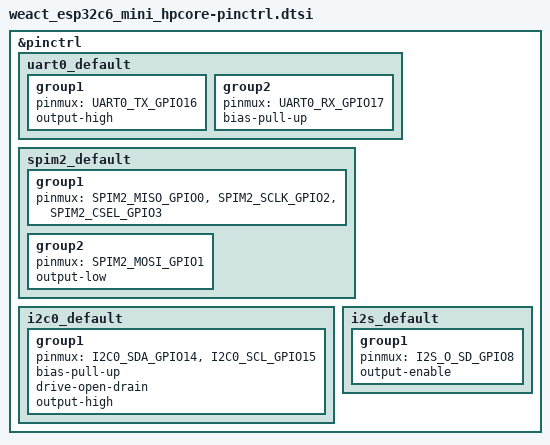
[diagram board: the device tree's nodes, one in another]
/*
 * Copyright (c) 2025 Siratul Islam
 *
 * SPDX-License-Identifier: Apache-2.0
 */

#include <zephyr/dt-bindings/pinctrl/esp-pinctrl-common.h>
#include <dt-bindings/pinctrl/esp32c6-pinctrl.h>
#include <zephyr/dt-bindings/pinctrl/esp32c6-gpio-sigmap.h>

&pinctrl {
	uart0_default: uart0_default {
		group1 {
			pinmux = <UART0_TX_GPIO16>;
			output-high;
		};

		group2 {
			pinmux = <UART0_RX_GPIO17>;
			bias-pull-up;
		};
	};

	spim2_default: spim2_default {
		group1 {
			pinmux = <SPIM2_MISO_GPIO0>,
				 <SPIM2_SCLK_GPIO2>,
				 <SPIM2_CSEL_GPIO3>;
		};

		group2 {
			pinmux = <SPIM2_MOSI_GPIO1>;
			output-low;
		};
	};

	i2c0_default: i2c0_default {
		group1 {
			pinmux = <I2C0_SDA_GPIO14>,
				 <I2C0_SCL_GPIO15>;
			bias-pull-up;
			drive-open-drain;
			output-high;
		};
	};

	i2s_default: i2s_default {
		group1 {
			pinmux = <I2S_O_SD_GPIO8>;
			output-enable;
		};
	};
};
